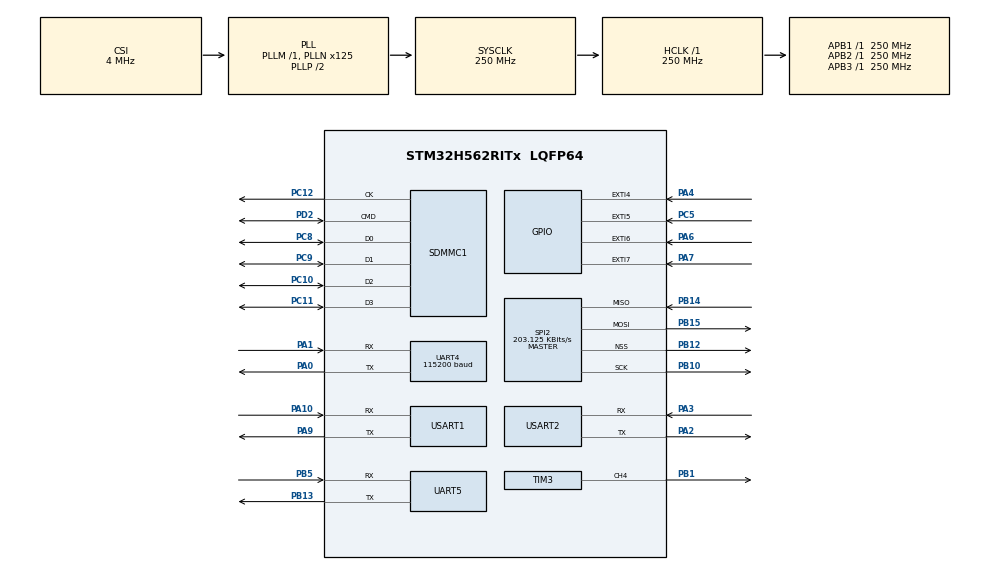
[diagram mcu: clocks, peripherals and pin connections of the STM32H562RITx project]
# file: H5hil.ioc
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BOOTPATH.BootPathName=LEGACY
BOOTPATH.UserSelectedBootPath=LEGACY
CORTEX_M33_NS.userName=CORTEX_M33
FILEX.FX_SD_INTERFACE=1
Mcu.Family=STM32H5
Mcu.Name=STM32H562RITx
Mcu.Package=LQFP64
NVIC.EXTI4_IRQn=true\:0\:0\:false\:false\:true\:true\:true\:true
NVIC.EXTI6_IRQn=true\:0\:0\:false\:false\:true\:true\:true\:true
NVIC.EXTI7_IRQn=true\:0\:0\:false\:false\:true\:true\:true\:true
NVIC.PriorityGroup=NVIC_PRIORITYGROUP_4
NVIC.TIM4_IRQn=true\:0\:0\:false\:false\:true\:true\:true\:true
NVIC.UART4_IRQn=true\:0\:0\:false\:false\:true\:true\:true\:true
PA0.Mode=Asynchronous
PA0.Signal=UART4_TX
PA1.Mode=Asynchronous
PA1.Signal=UART4_RX
PA10.Mode=Asynchronous
PA10.Signal=USART1_RX
PA2.Mode=Asynchronous
PA2.Signal=USART2_TX
PA3.Mode=Asynchronous
PA3.Signal=USART2_RX
PA4.GPIO_ModeDefaultEXTI=GPIO_MODE_IT_RISING_FALLING
PA4.GPIO_PuPd=GPIO_PULLDOWN
PA4.Signal=GPXTI4
PA6.GPIO_ModeDefaultEXTI=GPIO_MODE_IT_RISING_FALLING
PA6.GPIO_PuPd=GPIO_PULLDOWN
PA6.Signal=GPXTI6
PA7.GPIO_ModeDefaultEXTI=GPIO_MODE_IT_RISING_FALLING
PA7.GPIO_PuPd=GPIO_PULLDOWN
PA7.Signal=GPXTI7
PA9.Mode=Asynchronous
PA9.Signal=USART1_TX
PB1.Signal=S_TIM3_CH4
PB10.Mode=Full_Duplex_Master
PB10.Signal=SPI2_SCK
PB12.Mode=NSS_Signal_Hard_Output
PB12.Signal=SPI2_NSS
PB13.Mode=Asynchronous
PB13.Signal=UART5_TX
PB14.Mode=Full_Duplex_Master
PB14.Signal=SPI2_MISO
PB15.Mode=Full_Duplex_Master
PB15.Signal=SPI2_MOSI
PB5.Mode=Asynchronous
PB5.Signal=UART5_RX
PC10.Mode=SD_4_bits_Wide_bus
PC10.Signal=SDMMC1_D2
PC11.Mode=SD_4_bits_Wide_bus
PC11.Signal=SDMMC1_D3
PC12.Mode=SD_4_bits_Wide_bus
PC12.Signal=SDMMC1_CK
PC5.Signal=GPXTI5
PC8.Mode=SD_4_bits_Wide_bus
PC8.Signal=SDMMC1_D0
PC9.Mode=SD_4_bits_Wide_bus
PC9.Signal=SDMMC1_D1
PD2.Mode=SD_4_bits_Wide_bus
PD2.Signal=SDMMC1_CMD
ProjectManager.HeapSize=0x200
ProjectManager.StackSize=0x400
ProjectManager.TargetToolchain=STM32CubeIDE
RCC.ADCFreq_Value=250000000
RCC.AHBFreq_Value=250000000
RCC.APB1Freq_Value=250000000
RCC.APB1TimFreq_Value=250000000
RCC.APB2Freq_Value=250000000
RCC.APB2TimFreq_Value=250000000
RCC.APB3Freq_Value=250000000
RCC.CSI_VALUE=4000000
RCC.CortexFreq_Value=250000000
RCC.EPOD_VALUE=4000000
RCC.HCLKFreq_Value=250000000
RCC.HSE_VALUE=25000000
RCC.HSI48_VALUE=48000000
RCC.HSIDiv=RCC_HSI_DIV1
RCC.HSI_VALUE=64000000
RCC.LSE_VALUE=32768
RCC.LSIRC_VALUE=32000
RCC.PLL1Q=3
RCC.PLL2FRACN=0
RCC.PLL3FRACN=0
RCC.PLL3N=104
RCC.PLL3P=32
RCC.PLLFRACN=0
RCC.PLLN=125
RCC.SPI2CLockSelection=RCC_SPI2CLKSOURCE_PLL3P
RCC.SYSCLKFreq_VALUE=250000000
RCC.SYSCLKSource=RCC_SYSCLKSOURCE_PLLCLK
RCC.USBFreq_Value=48000000
RCC.VCOOutputFreq_Value=500000000
SH.S_TIM3_CH4.0=TIM3_CH4,PWM Generation4 CH4
SPI2.BaudRatePrescaler=SPI_BAUDRATEPRESCALER_64
SPI2.CalculateBaudRate=203.125 KBits/s
SPI2.DataSize=SPI_DATASIZE_8BIT
SPI2.Direction=SPI_DIRECTION_2LINES
SPI2.Mode=SPI_MODE_MASTER
SPI2.VirtualNSS=VM_NSSHARD
SPI2.VirtualType=VM_MASTER
TIM3.Channel-PWM\ Generation4\ CH4=TIM_CHANNEL_4
TIM3.PeriodNoDither=19999
TIM3.Prescaler=249
TIM3.PulseNoDither_4=1500
TIM4.AutoReloadPreload=TIM_AUTORELOAD_PRELOAD_DISABLE
TIM4.CounterMode=TIM_COUNTERMODE_UP
TIM4.Prescaler=199
UART4.BaudRate=115200
UART4.DataInvertParam=UART_ADVFEATURE_DATAINV_DISABLE
UART4.FIFOMode=FIFOMODE_ENABLE
UART4.Mode=MODE_RX
UART4.RxPinLevelInvertParam=UART_ADVFEATURE_RXINV_ENABLE
USART1.VirtualMode-Asynchronous=VM_ASYNC
USART2.VirtualMode-Asynchronous=VM_ASYNC
VP_BOOTPATH_VS_BOOTPATH.Mode=BP_Activate
VP_CORTEX_M33_NS_VS_Hclk.Mode=Hclk_Mode
VP_FILEX_VS_FileOoSystemJjFileXJjCore.Mode=FileX_Core
VP_FILEX_VS_SDOointerface.Mode=SD_interface
VP_ICACHE_VS_ICACHE.Mode=DefaultMode
VP_MEMORYMAP_VS_MEMORYMAP.Mode=CurAppReg
VP_PWR_VS_LPOM.Mode=PowerOptimisation
VP_PWR_VS_SECSignals.Mode=Security/Privilege
VP_RTC_VS_RTC_Activate.Mode=RTC_Enabled
VP_TIM3_VS_ClockSourceINT.Mode=Internal
VP_TIM4_VS_ClockSourceINT.Mode=Internal
board=custom

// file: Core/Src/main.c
/* USER CODE BEGIN Header */
/**
  ******************************************************************************
  * @file           : main.c
  * @brief          : Main program body
  ******************************************************************************
  */
/* USER CODE END Header */
#include "main.h"
#include "app_filex.h"
#include "icache.h"
#include "rtc.h"
#include "sdmmc.h"
#include "spi.h"
#include "tim.h"
#include "usart.h"
#include "gpio.h"

/* USER CODE BEGIN Includes */
#include "esc_app.h"
#include "encoder_app.h"
/* USER CODE END Includes */

void SystemClock_Config(void);

int main(void)
{

  /* MCU Configuration--------------------------------------------------------*/

  /* Reset of all peripherals, Initializes the Flash interface and the Systick. */
  HAL_Init();

  /* Configure the system clock */
  SystemClock_Config();

  /* Initialize all configured peripherals */
  MX_GPIO_Init();
  MX_TIM3_Init();
  MX_USART2_UART_Init();
  MX_SDMMC1_SD_Init();
  MX_ICACHE_Init();
  MX_SPI2_Init();
  MX_UART4_Init();
  MX_USART1_UART_Init();
  MX_UART5_Init();
  MX_FileX_Init();
  MX_RTC_Init();
  MX_TIM4_Init();
  /* USER CODE BEGIN 2 */
  ESC_App_Init();   /* starts PWM, arms ESC, then inits all app modules */
  /* USER CODE END 2 */

  /* Infinite loop */
  /* USER CODE BEGIN WHILE */
  while (1)
  {
      ESC_App_Task();
    /* USER CODE END WHILE */

  }
}

void SystemClock_Config(void)
{
  RCC_OscInitTypeDef RCC_OscInitStruct = {0};
  RCC_ClkInitTypeDef RCC_ClkInitStruct = {0};

  /** Configure the main internal regulator output voltage
  */
  __HAL_PWR_VOLTAGESCALING_CONFIG(PWR_REGULATOR_VOLTAGE_SCALE0);

  while(!__HAL_PWR_GET_FLAG(PWR_FLAG_VOSRDY)) {}

  /** Initializes the RCC Oscillators according to the specified parameters
  * in the RCC_OscInitTypeDef structure.
  */
  RCC_OscInitStruct.OscillatorType = RCC_OSCILLATORTYPE_LSI|RCC_OSCILLATORTYPE_CSI;
  RCC_OscInitStruct.LSIState = RCC_LSI_ON;
  RCC_OscInitStruct.CSIState = RCC_CSI_ON;
  RCC_OscInitStruct.CSICalibrationValue = RCC_CSICALIBRATION_DEFAULT;
  RCC_OscInitStruct.PLL.PLLState = RCC_PLL_ON;
  RCC_OscInitStruct.PLL.PLLSource = RCC_PLL1_SOURCE_CSI;
  RCC_OscInitStruct.PLL.PLLM = 1;
  RCC_OscInitStruct.PLL.PLLN = 125;
  RCC_OscInitStruct.PLL.PLLP = 2;
  RCC_OscInitStruct.PLL.PLLQ = 3;
  RCC_OscInitStruct.PLL.PLLR = 2;
  RCC_OscInitStruct.PLL.PLLRGE = RCC_PLL1_VCIRANGE_2;
  RCC_OscInitStruct.PLL.PLLVCOSEL = RCC_PLL1_VCORANGE_WIDE;
  RCC_OscInitStruct.PLL.PLLFRACN = 0;
  if (HAL_RCC_OscConfig(&RCC_OscInitStruct) != HAL_OK)
  {
    Error_Handler();
  }

  /** Initializes the CPU, AHB and APB buses clocks
  */
  RCC_ClkInitStruct.ClockType = RCC_CLOCKTYPE_HCLK|RCC_CLOCKTYPE_SYSCLK
                              |RCC_CLOCKTYPE_PCLK1|RCC_CLOCKTYPE_PCLK2
                              |RCC_CLOCKTYPE_PCLK3;
  RCC_ClkInitStruct.SYSCLKSource = RCC_SYSCLKSOURCE_PLLCLK;
  RCC_ClkInitStruct.AHBCLKDivider = RCC_SYSCLK_DIV1;
  RCC_ClkInitStruct.APB1CLKDivider = RCC_HCLK_DIV1;
  RCC_ClkInitStruct.APB2CLKDivider = RCC_HCLK_DIV1;
  RCC_ClkInitStruct.APB3CLKDivider = RCC_HCLK_DIV1;

  if (HAL_RCC_ClockConfig(&RCC_ClkInitStruct, FLASH_LATENCY_5) != HAL_OK)
  {
    Error_Handler();
  }

  /** Configure the programming delay
  */
  __HAL_FLASH_SET_PROGRAM_DELAY(FLASH_PROGRAMMING_DELAY_2);
}

void Error_Handler(void)
{
  __disable_irq();
  while (1) {}
}
#ifdef USE_FULL_ASSERT
/**
  * @brief  Reports the name of the source file and the source line number
  *         where the assert_param error has occurred.
  * @param  file: pointer to the source file name
  * @param  line: assert_param error line source number
  * @retval None
  */
void assert_failed(uint8_t *file, uint32_t line)
{
  /* USER CODE BEGIN 6 */
  (void)file;
  (void)line;
  /* USER CODE END 6 */
}
#endif /* USE_FULL_ASSERT */
